# soc register map
Vendor: litex
Registers are 32-bit, read-write, reset 0x0 unless marked. A register's access mark holds for its fields unless they carry their own. Offsets are from the block's base; [hi:lo] are bit positions.

## I2C
Base 0xF0003000
0x00 PRESCALE reset 0xFFFF — Prescaler value. Set to (module clock / (5 * I2C freq) - 1). Example: if module clock is equal to sysclk; syclk is 100MHz; and I2C freq is 100kHz, then prescaler is (100MHz / (5 * 100kHz) - 1) = 199. Reset value: 0xFFFF
  [15:0] prescale
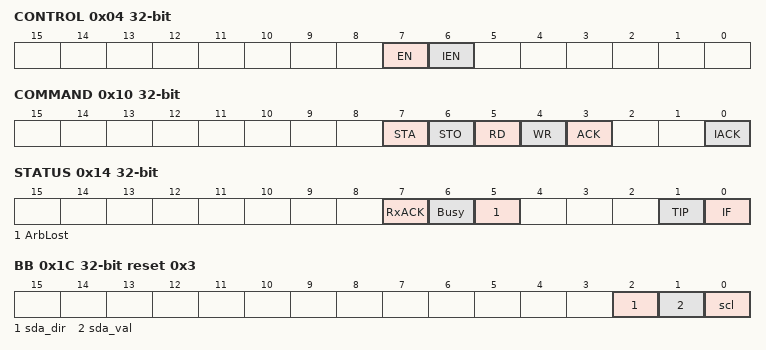
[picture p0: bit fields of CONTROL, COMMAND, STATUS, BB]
0x04 CONTROL
  [7] EN — When set to `1`, the core is enabled.
  [6] IEN — When set to `1`, interrupts are enabled.
0x08 TXR — Next byte to transmit to slave devices. LSB indicates R/W during address phases, `1` for reading from slaves, `0` for writing to slaves
  [7:0] txr
0x0C RXR — Data being read from slaved devices
  [7:0] rxr
0x10 COMMAND
  [7] STA — generate (repeated) start condition
  [6] STO — generate stop condition
  [5] RD — read from slave
  [4] WR — write to slave
  [3] ACK — when a receiver, sent ack (`ACK=0`) or nack (`ACK=1`)
  [0] IACK — Interrupt acknowledge; when set, clears a pending interrupt
0x14 STATUS
  [7] RxACK — Received acknowledge from slave. 1 = no ack received, 0 = ack received
  [6] Busy — I2C block is busy processing the latest command
  [5] ArbLost — Set when arbitration for the bus is lost
  [1] TIP — transfer in progress
  [0] IF — Interrupt flag, This bit is set when an interrupt is pending, which will cause a processor interrupt request if the IEN bit is set. The Interrupt Flag is set upon the completion of one byte of data transfer.
0x18 BITBANG_MODE — When set, I2C is driven by bitbang GPIO operations
  [0] bitbang_mode
0x1C BB reset 0x3
  [2] sda_dir — When `1`, drives SDA; `0` tristates
  [1] sda_val — Applies its value to SDA when `sda_dir` is 1
  [0] scl — Directly controls the SCL pin
0x20 BB_R — The value currently sensed on the SDA pin
  [0] bb_r
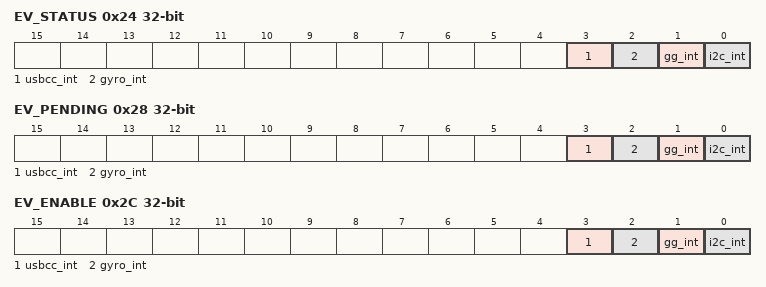
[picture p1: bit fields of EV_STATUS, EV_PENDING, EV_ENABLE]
0x24 EV_STATUS — USB CC register changed
  [3] usbcc_int — Level of the ``usbcc_int`` event
  [2] gyro_int — Level of the ``gyro_int`` event
  [1] gg_int — Level of the ``gg_int`` event
  [0] i2c_int — Level of the ``i2c_int`` event
0x28 EV_PENDING — USB CC register changed
  [3] usbcc_int — USB CC register changed
  [2] gyro_int — Gyro interrupt
  [1] gg_int — Gas gauge interrupt
  [0] i2c_int — I2C cycle completed
0x2C EV_ENABLE — USB CC register changed
  [3] usbcc_int — Write a ``1`` to enable the ``usbcc_int`` Event
  [2] gyro_int — Write a ``1`` to enable the ``gyro_int`` Event
  [1] gg_int — Write a ``1`` to enable the ``gg_int`` Event
  [0] i2c_int — Write a ``1`` to enable the ``i2c_int`` Event

## TICKTIMER
Base 0xF0003800
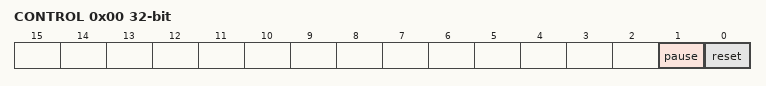
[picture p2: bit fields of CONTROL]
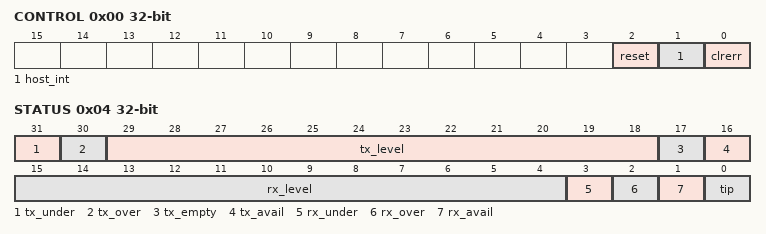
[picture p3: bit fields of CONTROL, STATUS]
0x00 CONTROL
  [1] pause — Write a `1` to this field to pause counting, 0 for free-run
  [0] reset — Write a `1` to this bit to reset the count to 0
0x04 TIME1 — Bits 32-39 of `TICKTIMER_TIME`. Elapsed time in systicks
  [31:0] time
0x08 TIME0 — Bits 0-31 of `TICKTIMER_TIME`.
  [31:0] time
0x0C MSLEEP_TARGET1 — Bits 32-39 of `TICKTIMER_MSLEEP_TARGET`. Target time in 1.0ms ticks
  [31:0] msleep_target
0x10 MSLEEP_TARGET0 — Bits 0-31 of `TICKTIMER_MSLEEP_TARGET`.
  [31:0] msleep_target
0x14 EV_STATUS — This register contains the current raw level of the alarm event trigger. Writes to this register have no effect.
  [0] alarm — Level of the ``alarm`` event
0x18 EV_PENDING — When a alarm event occurs, the corresponding bit will be set in this register. To clear the Event, set the corresponding bit in this register.
  [0] alarm — `1` if a `alarm` event occurred. This Event is **level triggered** when the signal is **high**.
0x1C EV_ENABLE — This register enables the corresponding alarm events. Write a ``0`` to this register to disable individual events.
  [0] alarm — Write a ``1`` to enable the ``alarm`` Event

## COM
Base 0xF0004000
0x00 CONTROL
  [2] reset — Reset the fifos
  [1] host_int — 0->1 raises an interrupt to the COM host
  [0] clrerr — Clear FIFO error flags
0x04 STATUS
  [31] tx_under — Set when Tx FIFO underflows
  [30] tx_over — Set when Tx FIFO overflows
  [29:18] tx_level — Level of Tx FIFO
  [17] tx_empty — Set when Tx FIFO is empty
  [16] tx_avail — Set when Tx FIFO has space for new content
  [15:4] rx_level — Level of Rx FIFO
  [3] rx_under — Set if Rx FIFO underflows
  [2] rx_over — Set if Rx FIFO has overflowed
  [1] rx_avail — Set when Rx FIFO has new, valid contents to read
  [0] tip — Set when transaction is in progress

## WIFI
Base 0xF0004800
0x00 TX — Tx data, for COPI
  [15:0] tx
0x04 RX — Rx data, from CIPO
  [15:0] rx
0x08 CS
  [0] cs — Writing `1` to this asserts cs_n, that is, brings it low; writing `0`, brings it high
0x0C CONTROL
  [0] go — Initiate a SPI cycle by writing a `1`. Does not automatically clear.
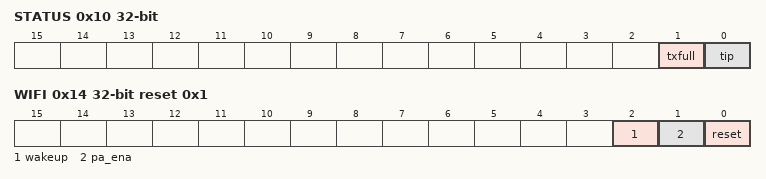
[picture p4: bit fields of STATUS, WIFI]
0x10 STATUS
  [1] txfull — Set when Tx register is full
  [0] tip — Set when transaction is in progress
0x14 WIFI reset 0x1
  [2] wakeup — Wakeup the wifi chip
  [1] pa_ena — Mapped to PA_ENABLE for wifi (only useful if configured in wifi firmware)
  [0] reset — Write `1` to this register to reset the wifi chip; write `0` to enable normal operation
0x18 EV_STATUS — Interrupt request from wifi chip
  [0] wirq — Level of the ``wirq`` event
0x1C EV_PENDING — Interrupt request from wifi chip
  [0] wirq
0x20 EV_ENABLE — Interrupt request from wifi chip
  [0] wirq — Write a ``1`` to enable the ``wirq`` Event

## CTRL
Base 0xF0005000
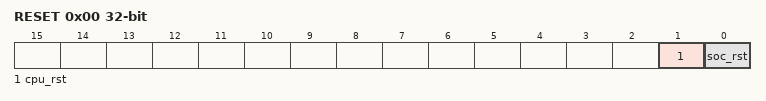
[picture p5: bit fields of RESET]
0x00 RESET
  [1] cpu_rst — Write `1` to this register to reset the CPU(s) of the SoC (Hold Reset)
  [0] soc_rst — Write `1` to this register to reset the full SoC (Pulse Reset)
0x04 SCRATCH reset 0x12345678 — Use this register as a scratch space to verify that software read/write accesses to the Wishbone/CSR bus are working correctly. The initial reset value of 0x1234578 can be used to verify endianness.
0x08 BUS_ERRORS — Total number of Wishbone bus errors (timeouts) since start.

## TIMER0
Base 0xF0005800
0x00 LOAD — Load value when Timer is (re-)enabled. In One-Shot mode, the value written to this register specifies the Timer's duration in clock cycles.
0x04 RELOAD — Reload value when Timer reaches ``0``. In Periodic mode, the value written to this register specify the Timer's period in clock cycles.
0x08 EN — Enable flag of the Timer. Set this flag to ``1`` to enable/start the Timer. Set to ``0`` to disable the Timer.
  [0] en
0x0C UPDATE_VALUE — Update trigger for the current countdown value. A write to this register latches the current countdown value to ``value`` register.
  [0] update_value
0x10 VALUE — Latched countdown value. This value is updated by writing to ``update_value``.
0x14 EV_STATUS — This register contains the current raw level of the zero event trigger. Writes to this register have no effect.
  [0] zero — Level of the ``zero`` event
0x18 EV_PENDING — When a zero event occurs, the corresponding bit will be set in this register. To clear the Event, set the corresponding bit in this register.
  [0] zero — `1` if a `zero` event occurred. This Event is triggered on a **falling** edge.
0x1C EV_ENABLE — This register enables the corresponding zero events. Write a ``0`` to this register to disable individual events.
  [0] zero — Write a ``1`` to enable the ``zero`` Event
